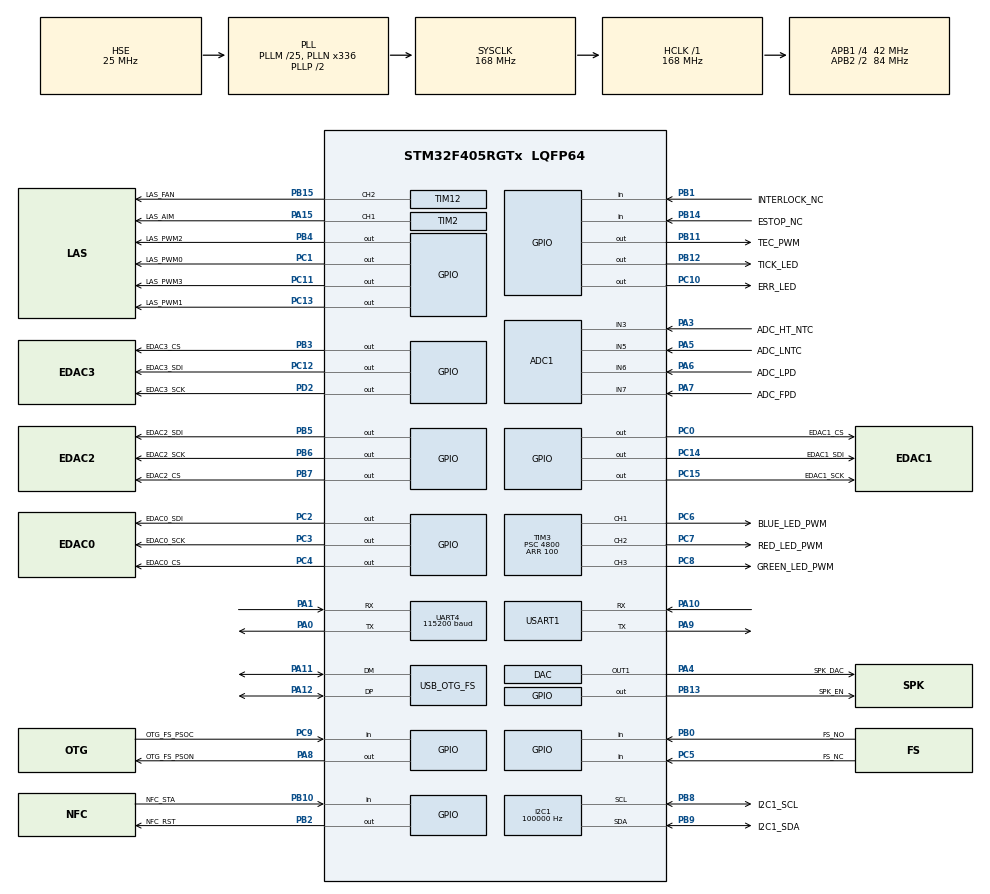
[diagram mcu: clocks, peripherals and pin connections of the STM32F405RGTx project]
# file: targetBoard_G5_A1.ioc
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ADC1.Channel-0\#ChannelRegularConversion=ADC_CHANNEL_3
ADC1.Channel-1\#ChannelRegularConversion=ADC_CHANNEL_5
ADC1.Channel-2\#ChannelRegularConversion=ADC_CHANNEL_6
ADC1.Channel-5\#ChannelRegularConversion=ADC_CHANNEL_7
ADC1.Channel-6\#ChannelRegularConversion=ADC_CHANNEL_TEMPSENSOR
ADC1.Channel-7\#ChannelRegularConversion=ADC_CHANNEL_VREFINT
ADC1.Channel-8\#ChannelRegularConversion=ADC_CHANNEL_VBAT
ADC1.ContinuousConvMode=ENABLE
ADC1.DMAContinuousRequests=ENABLE
ADC1.EOCSelection=ADC_EOC_SEQ_CONV
ADC1.NbrOfConversion=7
ADC1.NbrOfConversionFlag=1
ADC1.Rank-0\#ChannelRegularConversion=1
ADC1.Rank-1\#ChannelRegularConversion=2
ADC1.Rank-2\#ChannelRegularConversion=3
ADC1.Rank-5\#ChannelRegularConversion=4
ADC1.Rank-6\#ChannelRegularConversion=5
ADC1.Rank-7\#ChannelRegularConversion=6
ADC1.Rank-8\#ChannelRegularConversion=7
ADC1.SamplingTime-0\#ChannelRegularConversion=ADC_SAMPLETIME_144CYCLES
ADC1.SamplingTime-1\#ChannelRegularConversion=ADC_SAMPLETIME_144CYCLES
ADC1.SamplingTime-2\#ChannelRegularConversion=ADC_SAMPLETIME_144CYCLES
ADC1.SamplingTime-5\#ChannelRegularConversion=ADC_SAMPLETIME_144CYCLES
ADC1.SamplingTime-6\#ChannelRegularConversion=ADC_SAMPLETIME_144CYCLES
ADC1.SamplingTime-7\#ChannelRegularConversion=ADC_SAMPLETIME_144CYCLES
ADC1.SamplingTime-8\#ChannelRegularConversion=ADC_SAMPLETIME_144CYCLES
ADC1.ScanConvMode=ENABLE
ADC1.master=1
DAC.DAC_Trigger=DAC_TRIGGER_T7_TRGO
Dma.ADC1.1.Direction=DMA_PERIPH_TO_MEMORY
Dma.ADC1.1.FIFOMode=DMA_FIFOMODE_DISABLE
Dma.ADC1.1.Instance=DMA2_Stream0
Dma.ADC1.1.MemDataAlignment=DMA_MDATAALIGN_HALFWORD
Dma.ADC1.1.MemInc=DMA_MINC_ENABLE
Dma.ADC1.1.Mode=DMA_NORMAL
Dma.ADC1.1.PeriphDataAlignment=DMA_PDATAALIGN_HALFWORD
Dma.ADC1.1.PeriphInc=DMA_PINC_DISABLE
Dma.ADC1.1.Priority=DMA_PRIORITY_LOW
Dma.DAC1.0.Direction=DMA_MEMORY_TO_PERIPH
Dma.DAC1.0.FIFOMode=DMA_FIFOMODE_DISABLE
Dma.DAC1.0.Instance=DMA1_Stream5
Dma.DAC1.0.MemDataAlignment=DMA_MDATAALIGN_HALFWORD
Dma.DAC1.0.MemInc=DMA_MINC_ENABLE
Dma.DAC1.0.Mode=DMA_CIRCULAR
Dma.DAC1.0.PeriphDataAlignment=DMA_PDATAALIGN_HALFWORD
Dma.DAC1.0.PeriphInc=DMA_PINC_DISABLE
Dma.DAC1.0.Priority=DMA_PRIORITY_LOW
Dma.Request0=DAC1
Dma.Request1=ADC1
FATFS._CODE_PAGE=437
FATFS._FS_EXFAT=1
FATFS._FS_LOCK=255
FATFS._LFN_UNICODE=0
FATFS._STRF_ENCODE=0
FATFS._USE_CHMOD=1
FATFS._USE_EXPAND=1
FATFS._USE_FIND=1
FATFS._USE_FORWARD=1
FATFS._USE_LABEL=1
FATFS._USE_LFN=2
FATFS._USE_MUTEX=1
FATFS._USE_TRIM=1
FREERTOS.Tasks01=defaultTask,24,512,StartDefaultTask,Default,NULL,Dynamic,NULL,NULL
FREERTOS.configENABLE_FPU=1
FREERTOS.configMINIMAL_STACK_SIZE=512
FREERTOS.configTOTAL_HEAP_SIZE=49152
FREERTOS.configUSE_APPLICATION_TASK_TAG=1
I2C1.ClockSpeed=100000
I2C1.I2C_Mode=I2C_Standard
Mcu.Family=STM32F4
Mcu.Name=STM32F405RGTx
Mcu.Package=LQFP64
NVIC.ADC_IRQn=true\:5\:0\:false\:false\:true\:true\:true\:true\:true
NVIC.DMA1_Stream5_IRQn=true\:5\:0\:false\:false\:true\:true\:false\:true\:true
NVIC.DMA2_Stream0_IRQn=true\:5\:0\:false\:false\:true\:true\:false\:true\:true
NVIC.OTG_FS_IRQn=true\:5\:0\:false\:false\:true\:true\:true\:true\:true
NVIC.PriorityGroup=NVIC_PRIORITYGROUP_4
NVIC.RCC_IRQn=true\:5\:0\:false\:false\:true\:true\:true\:false\:true
NVIC.TIM1_UP_TIM10_IRQn=true\:5\:0\:false\:false\:true\:true\:true\:true\:true
NVIC.TIM6_DAC_IRQn=true\:15\:0\:false\:false\:true\:false\:false\:true\:true
NVIC.TIM8_TRG_COM_TIM14_IRQn=true\:5\:0\:false\:false\:true\:true\:true\:true\:true
NVIC.TimeBase=TIM6_DAC_IRQn
NVIC.TimeBaseIP=TIM6
NVIC.UART4_IRQn=true\:5\:0\:false\:false\:true\:true\:true\:true\:true
PA0-WKUP.GPIO_PuPd=GPIO_PULLDOWN
PA0-WKUP.GPIO_Speed=GPIO_SPEED_FREQ_LOW
PA0-WKUP.Mode=Asynchronous
PA0-WKUP.Signal=UART4_TX
PA1.GPIO_PuPd=GPIO_PULLDOWN
PA1.GPIO_Speed=GPIO_SPEED_FREQ_LOW
PA1.Mode=Asynchronous
PA1.Signal=UART4_RX
PA10.GPIO_PuPd=GPIO_NOPULL
PA10.GPIO_Speed=GPIO_SPEED_FREQ_LOW
PA10.Mode=Asynchronous
PA10.Signal=USART1_RX
PA11.Mode=Host_Only
PA11.Signal=USB_OTG_FS_DM
PA12.Mode=Host_Only
PA12.Signal=USB_OTG_FS_DP
PA13.Mode=Serial_Wire
PA13.Signal=SYS_JTMS-SWDIO
PA14.Mode=Serial_Wire
PA14.Signal=SYS_JTCK-SWCLK
PA15.GPIO_Label=LAS_AIM
PA15.GPIO_PuPd=GPIO_PULLDOWN
PA15.Signal=S_TIM2_CH1_ETR
PA3.GPIO_Label=ADC_HT_NTC
PA3.Signal=ADCx_IN3
PA4.GPIO_Label=SPK_DAC
PA4.Signal=COMP_DAC1_group
PA5.GPIO_Label=ADC_LNTC
PA5.Signal=ADCx_IN5
PA6.GPIO_Label=ADC_LPD
PA6.Signal=ADCx_IN6
PA7.GPIO_Label=ADC_FPD
PA7.Signal=ADCx_IN7
PA8.GPIO_Label=OTG_FS_PSON
PA8.GPIO_PuPd=GPIO_PULLDOWN
PA8.Signal=GPIO_Output
PA9.GPIO_PuPd=GPIO_NOPULL
PA9.GPIO_Speed=GPIO_SPEED_FREQ_LOW
PA9.Mode=Asynchronous
PA9.Signal=USART1_TX
PB0.GPIO_Label=FS_NO
PB0.GPIO_PuPd=GPIO_PULLUP
PB0.Signal=GPIO_Input
PB1.GPIO_Label=INTERLOCK_NC
PB1.Signal=GPIO_Input
PB10.GPIO_Label=NFC_STA
PB10.GPIO_PuPd=GPIO_PULLUP
PB10.Signal=GPIO_Input
PB11.GPIO_Label=TEC_PWM
PB11.Signal=GPIO_Output
PB12.GPIO_Label=TICK_LED
PB12.GPIO_PuPd=GPIO_PULLUP
PB12.GPIO_Speed=GPIO_SPEED_FREQ_LOW
PB12.PinState=GPIO_PIN_SET
PB12.Signal=GPIO_Output
PB13.GPIO_Label=SPK_EN
PB13.GPIO_PuPd=GPIO_PULLDOWN
PB13.Signal=GPIO_Output
PB14.GPIO_Label=ESTOP_NC
PB14.GPIO_PuPd=GPIO_PULLUP
PB14.Signal=GPIO_Input
PB15.GPIO_Label=LAS_FAN
PB15.Signal=S_TIM12_CH2
PB2.GPIO_Label=NFC_RST
PB2.GPIO_PuPd=GPIO_PULLUP
PB2.Signal=GPIO_Output
PB3.GPIO_Label=EDAC3_CS
PB3.GPIO_PuPd=GPIO_PULLDOWN
PB3.Signal=GPIO_Output
PB4.GPIO_Label=LAS_PWM2
PB4.GPIO_PuPd=GPIO_PULLDOWN
PB4.Signal=GPIO_Output
PB5.GPIO_Label=EDAC2_SDI
PB5.GPIO_PuPd=GPIO_PULLDOWN
PB5.Signal=GPIO_Output
PB6.GPIO_Label=EDAC2_SCK
PB6.GPIO_PuPd=GPIO_PULLDOWN
PB6.Signal=GPIO_Output
PB7.GPIO_Label=EDAC2_CS
PB7.GPIO_PuPd=GPIO_PULLUP
PB7.GPIO_Speed=GPIO_SPEED_FREQ_LOW
PB7.Signal=GPIO_Output
PB8.GPIO_Label=I2C1_SCL
PB8.GPIO_Pu=GPIO_PULLUP
PB8.GPIO_Speed=GPIO_SPEED_FREQ_MEDIUM
PB8.Mode=I2C
PB8.Signal=I2C1_SCL
PB9.GPIO_Label=I2C1_SDA
PB9.GPIO_Pu=GPIO_PULLUP
PB9.GPIO_Speed=GPIO_SPEED_FREQ_MEDIUM
PB9.Mode=I2C
PB9.Signal=I2C1_SDA
PC0.GPIO_Label=EDAC1_CS
PC0.GPIO_PuPd=GPIO_PULLUP
PC0.GPIO_Speed=GPIO_SPEED_FREQ_LOW
PC0.Signal=GPIO_Output
PC1.GPIO_Label=LAS_PWM0
PC1.GPIO_PuPd=GPIO_PULLDOWN
PC1.Signal=GPIO_Output
PC10.GPIO_Label=ERR_LED
PC10.GPIO_PuPd=GPIO_PULLDOWN
PC10.Signal=GPIO_Output
PC11.GPIO_Label=LAS_PWM3
PC11.GPIO_PuPd=GPIO_PULLDOWN
PC11.Signal=GPIO_Output
PC12.GPIO_Label=EDAC3_SDI
PC12.GPIO_PuPd=GPIO_PULLDOWN
PC12.Signal=GPIO_Output
PC13-ANTI_TAMP.GPIO_Label=LAS_PWM1
PC13-ANTI_TAMP.GPIO_PuPd=GPIO_PULLDOWN
PC13-ANTI_TAMP.Signal=GPIO_Output
PC14-OSC32_IN.GPIO_Label=EDAC1_SDI
PC14-OSC32_IN.GPIO_PuPd=GPIO_PULLDOWN
PC14-OSC32_IN.Signal=GPIO_Output
PC15-OSC32_OUT.GPIO_Label=EDAC1_SCK
PC15-OSC32_OUT.GPIO_PuPd=GPIO_PULLDOWN
PC15-OSC32_OUT.GPIO_Speed=GPIO_SPEED_FREQ_LOW
PC15-OSC32_OUT.Signal=GPIO_Output
PC2.GPIO_Label=EDAC0_SDI
PC2.GPIO_PuPd=GPIO_PULLDOWN
PC2.GPIO_Speed=GPIO_SPEED_FREQ_LOW
PC2.Signal=GPIO_Output
PC3.GPIO_Label=EDAC0_SCK
PC3.GPIO_PuPd=GPIO_PULLDOWN
PC3.GPIO_Speed=GPIO_SPEED_FREQ_LOW
PC3.Signal=GPIO_Output
PC4.GPIO_Label=EDAC0_CS
PC4.Signal=GPIO_Output
PC5.GPIO_Label=FS_NC
PC5.GPIO_PuPd=GPIO_PULLUP
PC5.Signal=GPIO_Input
PC6.GPIO_Label=BLUE_LED_PWM
PC6.Signal=S_TIM3_CH1
PC7.GPIO_Label=RED_LED_PWM
PC7.Signal=S_TIM3_CH2
PC8.GPIO_Label=GREEN_LED_PWM
PC8.Signal=S_TIM3_CH3
PC9.GPIO_Label=OTG_FS_PSOC
PC9.GPIO_PuPd=GPIO_PULLUP
PC9.Signal=GPIO_Input
PD2.GPIO_Label=EDAC3_SCK
PD2.GPIO_PuPd=GPIO_PULLUP
PD2.Signal=GPIO_Output
PH0-OSC_IN.Mode=HSE-External-Oscillator
PH0-OSC_IN.Signal=RCC_OSC_IN
PH1-OSC_OUT.Mode=HSE-External-Oscillator
PH1-OSC_OUT.Signal=RCC_OSC_OUT
ProjectManager.HeapSize=0x2000
ProjectManager.StackSize=0x2000
ProjectManager.TargetToolchain=MDK-ARM V5.32
RCC.48MHZClocksFreq_Value=48000000
RCC.AHBFreq_Value=168000000
RCC.APB1CLKDivider=RCC_HCLK_DIV4
RCC.APB1Freq_Value=42000000
RCC.APB1TimFreq_Value=84000000
RCC.APB2CLKDivider=RCC_HCLK_DIV2
RCC.APB2Freq_Value=84000000
RCC.APB2TimFreq_Value=168000000
RCC.CortexFreq_Value=168000000
RCC.EnbaleCSS=true
RCC.HCLKFreq_Value=168000000
RCC.HSE_VALUE=25000000
RCC.HSI_VALUE=16000000
RCC.LSE_VALUE=32768
RCC.PLLM=25
RCC.PLLN=336
RCC.PLLQ=7
RCC.SYSCLKFreq_VALUE=168000000
RCC.SYSCLKSource=RCC_SYSCLKSOURCE_PLLCLK
RCC.VCOOutputFreq_Value=336000000
SH.ADCx_IN3.0=ADC1_IN3,IN3
SH.ADCx_IN5.0=ADC1_IN5,IN5
SH.ADCx_IN6.0=ADC1_IN6,IN6
SH.ADCx_IN7.0=ADC1_IN7,IN7
SH.COMP_DAC1_group.0=DAC_OUT1,DAC_OUT1
SH.S_TIM12_CH2.0=TIM12_CH2,PWM Generation2 CH2
SH.S_TIM2_CH1_ETR.0=TIM2_CH1,PWM Generation1 CH1
SH.S_TIM3_CH1.0=TIM3_CH1,PWM Generation1 CH1
SH.S_TIM3_CH2.0=TIM3_CH2,PWM Generation2 CH2
SH.S_TIM3_CH3.0=TIM3_CH3,PWM Generation3 CH3
TIM10.AutoReloadPreload=TIM_AUTORELOAD_PRELOAD_ENABLE
TIM10.Period=1000
TIM10.Prescaler=168
TIM12.AutoReloadPreload=TIM_AUTORELOAD_PRELOAD_ENABLE
TIM12.Channel-PWM\ Generation2\ CH2=TIM_CHANNEL_2
TIM12.ClockDivision=TIM_CLOCKDIVISION_DIV1
TIM12.Period=100
TIM12.Prescaler=35
TIM14.AutoReloadPreload=TIM_AUTORELOAD_PRELOAD_ENABLE
TIM14.Period=1000
TIM14.Prescaler=84
TIM2.AutoReloadPreload=TIM_AUTORELOAD_PRELOAD_ENABLE
TIM2.Channel-PWM\ Generation1\ CH1=TIM_CHANNEL_1
TIM2.Period=5000
TIM2.Prescaler=96
TIM3.AutoReloadPreload=TIM_AUTORELOAD_PRELOAD_ENABLE
TIM3.Channel-PWM\ Generation1\ CH1=TIM_CHANNEL_1
TIM3.Channel-PWM\ Generation2\ CH2=TIM_CHANNEL_2
TIM3.Channel-PWM\ Generation3\ CH3=TIM_CHANNEL_3
TIM3.Period=100
TIM3.Prescaler=4800
TIM7.AutoReloadPreload=TIM_AUTORELOAD_PRELOAD_ENABLE
TIM7.Period=30
TIM7.Prescaler=10
TIM7.TIM_MasterOutputTrigger=TIM_TRGO_UPDATE
UART4.BaudRate=115200
UART4.VirtualMode=Asynchronous
USART1.VirtualMode=VM_ASYNC
USB_HOST.BSP.number=1
USB_HOST.USBH_DEBUG_LEVEL-ALL_Classes_FS=3
USB_HOST.USBH_HandleTypeDef-ALL_Classes_FS=hUsbHostFS
USB_HOST.USBH_MAX_DATA_BUFFER-ALL_Classes_FS=1024
USB_HOST.VirtualModeFS=All_Classes
USB_HOST0.BSP.STBoard=false
USB_HOST0.BSP.api=Unknown
USB_HOST0.BSP.instance=PA8
USB_HOST0.BSP.ip=GPIO
USB_HOST0.BSP.mode=Output
USB_HOST0.BSP.name=Drive_VBUS_FS
USB_HOST0.BSP.solution=PA8
USB_OTG_FS.VirtualMode=Host_Only
USB_OTG_FS.phy_itface=HCD_PHY_EMBEDDED
VP_ADC1_TempSens_Input.Mode=IN-TempSens
VP_ADC1_Vbat_Input.Mode=IN-Vbat
VP_ADC1_Vref_Input.Mode=IN-Vrefint
VP_CRC_VS_CRC.Mode=CRC_Activate
VP_FATFS_VS_USB.Mode=USB
VP_FREERTOS_VS_CMSIS_V2.Mode=CMSIS_V2
VP_RNG_VS_RNG.Mode=RNG_Activate
VP_SYS_VS_tim6.Mode=TIM6
VP_TIM10_VS_ClockSourceINT.Mode=Enable_Timer
VP_TIM12_VS_ClockSourceINT.Mode=Internal
VP_TIM14_VS_ClockSourceINT.Mode=Enable_Timer
VP_TIM2_VS_ClockSourceINT.Mode=Internal
VP_TIM3_VS_ClockSourceINT.Mode=Internal
VP_TIM7_VS_ClockSourceINT.Mode=Enable_Timer
VP_USB_HOST_VS_USB_HOST_ALL_CLASS_FS.Mode=ALL_Classes_FS
board=custom

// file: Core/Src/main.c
/* USER CODE BEGIN Header */
/**
  ******************************************************************************
  * @file           : main.c
  * @brief          : Main program body
  ******************************************************************************
  * @attention
  *
  * Copyright (c) 2025 STMicroelectronics.
  * All rights reserved.
  *
  * This software is licensed under terms that can be found in the LICENSE file
  * in the root directory of this software component.
  * If no LICENSE file comes with this software, it is provided AS-IS.
  *
  ******************************************************************************
  */
/* USER CODE END Header */
#include "main.h"
#include "cmsis_os.h"
#include "adc.h"
#include "crc.h"
#include "dac.h"
#include "dma.h"
#include "fatfs.h"
#include "i2c.h"
#include "rng.h"
#include "tim.h"
#include "usart.h"
#include "usb_host.h"
#include "gpio.h"

/* USER CODE BEGIN PTD */
#include "sPlc.h"
/* USER CODE END PTD */

void SystemClock_Config(void);
void MX_FREERTOS_Init(void);

int main(void)
{

  /* MCU Configuration--------------------------------------------------------*/

  /* Reset of all peripherals, Initializes the Flash interface and the Systick. */
  HAL_Init();

  /* Configure the system clock */
  SystemClock_Config();

  /* Initialize all configured peripherals */
  MX_GPIO_Init();
  MX_DMA_Init();
  MX_ADC1_Init();
  MX_DAC_Init();
  MX_I2C1_Init();
  MX_TIM2_Init();
  MX_UART4_Init();
  MX_USART1_UART_Init();
  MX_CRC_Init();
  MX_RNG_Init();
  MX_TIM7_Init();
  MX_TIM10_Init();
  MX_TIM14_Init();
  MX_TIM12_Init();
  MX_TIM3_Init();
  MX_FATFS_Init();

  /* Init scheduler */
  osKernelInitialize();  /* Call init function for freertos objects (in cmsis_os2.c) */
  MX_FREERTOS_Init();

  /* Start scheduler */
  osKernelStart();

  /* We should never get here as control is now taken by the scheduler */

  /* Infinite loop */
  while (1)
  {

  }
}

void SystemClock_Config(void)
{
  RCC_OscInitTypeDef RCC_OscInitStruct = {0};
  RCC_ClkInitTypeDef RCC_ClkInitStruct = {0};

  /** Configure the main internal regulator output voltage
  */
  __HAL_RCC_PWR_CLK_ENABLE();
  __HAL_PWR_VOLTAGESCALING_CONFIG(PWR_REGULATOR_VOLTAGE_SCALE1);

  /** Initializes the RCC Oscillators according to the specified parameters
  * in the RCC_OscInitTypeDef structure.
  */
  RCC_OscInitStruct.OscillatorType = RCC_OSCILLATORTYPE_HSE;
  RCC_OscInitStruct.HSEState = RCC_HSE_ON;
  RCC_OscInitStruct.PLL.PLLState = RCC_PLL_ON;
  RCC_OscInitStruct.PLL.PLLSource = RCC_PLLSOURCE_HSE;
  RCC_OscInitStruct.PLL.PLLM = 25;
  RCC_OscInitStruct.PLL.PLLN = 336;
  RCC_OscInitStruct.PLL.PLLP = RCC_PLLP_DIV2;
  RCC_OscInitStruct.PLL.PLLQ = 7;
  if (HAL_RCC_OscConfig(&RCC_OscInitStruct) != HAL_OK)
  {
    Error_Handler();
  }

  /** Initializes the CPU, AHB and APB buses clocks
  */
  RCC_ClkInitStruct.ClockType = RCC_CLOCKTYPE_HCLK|RCC_CLOCKTYPE_SYSCLK
                              |RCC_CLOCKTYPE_PCLK1|RCC_CLOCKTYPE_PCLK2;
  RCC_ClkInitStruct.SYSCLKSource = RCC_SYSCLKSOURCE_PLLCLK;
  RCC_ClkInitStruct.AHBCLKDivider = RCC_SYSCLK_DIV1;
  RCC_ClkInitStruct.APB1CLKDivider = RCC_HCLK_DIV4;
  RCC_ClkInitStruct.APB2CLKDivider = RCC_HCLK_DIV2;

  if (HAL_RCC_ClockConfig(&RCC_ClkInitStruct, FLASH_LATENCY_5) != HAL_OK)
  {
    Error_Handler();
  }

  /** Enables the Clock Security System
  */
  HAL_RCC_EnableCSS();
}

void HAL_TIM_PeriodElapsedCallback(TIM_HandleTypeDef *htim)
{
  if (htim->Instance == TIM6)
  {
    HAL_IncTick();
  }
  /* USER CODE BEGIN Callback 1 */
	if(htim->Instance == TIM14) {
		sPlcTimerIsr();
	}
	if(htim->Instance == TIM10){
		sPlcLaserTimerIsr();
	}
  /* USER CODE END Callback 1 */
}

void Error_Handler(void)
{
  __disable_irq();
  while (1)
  {
  }
}

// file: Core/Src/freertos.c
/* USER CODE BEGIN Header */
/**
  ******************************************************************************
  * File Name          : freertos.c
  * Description        : Code for freertos applications
  ******************************************************************************
  * @attention
  *
  * Copyright (c) 2025 STMicroelectronics.
  * All rights reserved.
  *
  * This software is licensed under terms that can be found in the LICENSE file
  * in the root directory of this software component.
  * If no LICENSE file comes with this software, it is provided AS-IS.
  *
  ******************************************************************************
  */
/* USER CODE END Header */

#include "FreeRTOS.h"
#include "task.h"
#include "main.h"
#include "cmsis_os.h"

/* USER CODE BEGIN Includes */
#include "mainApp.h"
/* USER CODE END Includes */

/* Definitions for defaultTask */
osThreadId_t defaultTaskHandle;
const osThreadAttr_t defaultTask_attributes = {
  .name = "defaultTask",
  .stack_size = 512 * 4,
  .priority = (osPriority_t) osPriorityNormal,
};

/* USER CODE BEGIN FunctionPrototypes */
osThreadId_t mainAppTaskHandle;
const osThreadAttr_t mainAppTask_attributes = {
  .name = "mainAppTask",
  .priority = (osPriority_t) osPriorityNormal,
  .stack_size = 1024 * 16
};
/* USER CODE END FunctionPrototypes */

void StartDefaultTask(void *argument);

extern void MX_USB_HOST_Init(void);
void MX_FREERTOS_Init(void); /* (MISRA C 2004 rule 8.1) */

void MX_FREERTOS_Init(void) {

  /* Create the thread(s) */
  /* creation of defaultTask */
  defaultTaskHandle = osThreadNew(StartDefaultTask, NULL, &defaultTask_attributes);

  /* USER CODE BEGIN RTOS_THREADS */
	mainAppTaskHandle = osThreadNew(mainAppTask, NULL, &mainAppTask_attributes);
  /* add threads, ... */
  /* USER CODE END RTOS_THREADS */

}

void StartDefaultTask(void *argument)
{
  /* init code for USB_HOST */
  MX_USB_HOST_Init();
  for(;;)
  {
    osDelay(1);
  }
}
